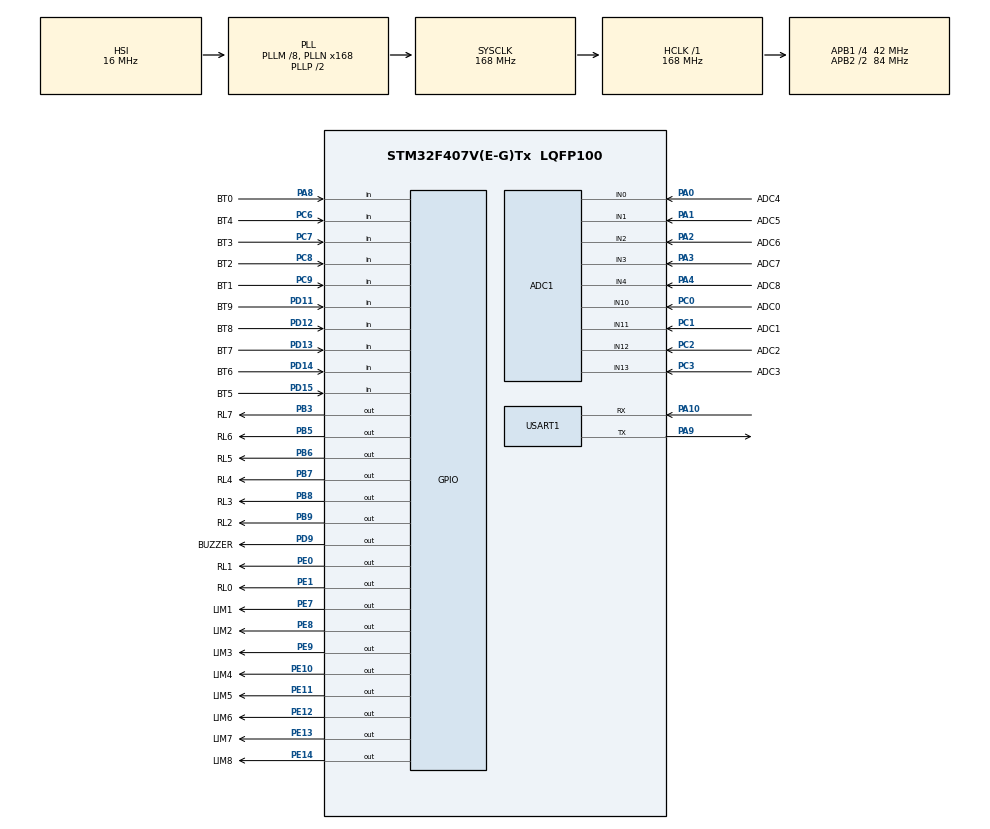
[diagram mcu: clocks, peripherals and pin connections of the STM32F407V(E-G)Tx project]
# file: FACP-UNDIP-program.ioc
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ADC1.Channel-16\#ChannelRegularConversion=ADC_CHANNEL_10
ADC1.NbrOfConversionFlag=1
ADC1.Rank-16\#ChannelRegularConversion=1
ADC1.SamplingTime-16\#ChannelRegularConversion=ADC_SAMPLETIME_3CYCLES
ADC1.master=1
Dma.Request0=USART1_RX
Dma.USART1_RX.0.Direction=DMA_PERIPH_TO_MEMORY
Dma.USART1_RX.0.FIFOMode=DMA_FIFOMODE_DISABLE
Dma.USART1_RX.0.Instance=DMA2_Stream2
Dma.USART1_RX.0.MemDataAlignment=DMA_MDATAALIGN_BYTE
Dma.USART1_RX.0.MemInc=DMA_MINC_ENABLE
Dma.USART1_RX.0.Mode=DMA_NORMAL
Dma.USART1_RX.0.PeriphDataAlignment=DMA_PDATAALIGN_BYTE
Dma.USART1_RX.0.PeriphInc=DMA_PINC_DISABLE
Dma.USART1_RX.0.Priority=DMA_PRIORITY_LOW
Mcu.Family=STM32F4
Mcu.Name=STM32F407V(E-G)Tx
Mcu.Package=LQFP100
NVIC.DMA2_Stream2_IRQn=true\:0\:0\:false\:false\:true\:false\:true\:true
NVIC.PriorityGroup=NVIC_PRIORITYGROUP_4
NVIC.USART1_IRQn=true\:0\:0\:false\:false\:true\:true\:true\:true
PA0-WKUP.GPIO_Label=ADC4
PA0-WKUP.Signal=ADCx_IN0
PA1.GPIO_Label=ADC5
PA1.Signal=ADCx_IN1
PA10.Mode=Asynchronous
PA10.Signal=USART1_RX
PA13.Mode=Serial_Wire
PA13.Signal=SYS_JTMS-SWDIO
PA14.Mode=Serial_Wire
PA14.Signal=SYS_JTCK-SWCLK
PA2.GPIO_Label=ADC6
PA2.Signal=ADCx_IN2
PA3.GPIO_Label=ADC7
PA3.Signal=ADCx_IN3
PA4.GPIO_Label=ADC8
PA4.Signal=ADCx_IN4
PA8.GPIO_Label=BT0
PA8.Signal=GPIO_Input
PA9.Mode=Asynchronous
PA9.Signal=USART1_TX
PB3.GPIO_Label=RL7
PB3.Signal=GPIO_Output
PB5.GPIO_Label=RL6
PB5.Signal=GPIO_Output
PB6.GPIO_Label=RL5
PB6.Signal=GPIO_Output
PB7.GPIO_Label=RL4
PB7.Signal=GPIO_Output
PB8.GPIO_Label=RL3
PB8.Signal=GPIO_Output
PB9.GPIO_Label=RL2
PB9.Signal=GPIO_Output
PC0.GPIO_Label=ADC0
PC0.Signal=ADCx_IN10
PC1.GPIO_Label=ADC1
PC1.Signal=ADCx_IN11
PC2.GPIO_Label=ADC2
PC2.Signal=ADCx_IN12
PC3.GPIO_Label=ADC3
PC3.Signal=ADCx_IN13
PC6.GPIO_Label=BT4
PC6.Signal=GPIO_Input
PC7.GPIO_Label=BT3
PC7.Signal=GPIO_Input
PC8.GPIO_Label=BT2
PC8.Signal=GPIO_Input
PC9.GPIO_Label=BT1
PC9.Signal=GPIO_Input
PD11.GPIO_Label=BT9
PD11.Signal=GPIO_Input
PD12.GPIO_Label=BT8
PD12.Signal=GPIO_Input
PD13.GPIO_Label=BT7
PD13.Signal=GPIO_Input
PD14.GPIO_Label=BT6
PD14.Signal=GPIO_Input
PD15.GPIO_Label=BT5
PD15.Signal=GPIO_Input
PD9.GPIO_Label=BUZZER
PD9.Signal=GPIO_Output
PE0.GPIO_Label=RL1
PE0.Signal=GPIO_Output
PE1.GPIO_Label=RL0
PE1.Signal=GPIO_Output
PE10.GPIO_Label=LIM4
PE10.Signal=GPIO_Output
PE11.GPIO_Label=LIM5
PE11.Signal=GPIO_Output
PE12.GPIO_Label=LIM6
PE12.Signal=GPIO_Output
PE13.GPIO_Label=LIM7
PE13.Signal=GPIO_Output
PE14.GPIO_Label=LIM8
PE14.Signal=GPIO_Output
PE7.GPIO_Label=LIM1
PE7.Signal=GPIO_Output
PE8.GPIO_Label=LIM2
PE8.Signal=GPIO_Output
PE9.GPIO_Label=LIM3
PE9.Signal=GPIO_Output
PH0-OSC_IN.Mode=HSE-External-Oscillator
PH0-OSC_IN.Signal=RCC_OSC_IN
PH1-OSC_OUT.Mode=HSE-External-Oscillator
PH1-OSC_OUT.Signal=RCC_OSC_OUT
ProjectManager.HeapSize=0x200
ProjectManager.StackSize=0x400
ProjectManager.TargetToolchain=MDK-ARM V5.32
RCC.48MHZClocksFreq_Value=84000000
RCC.AHBFreq_Value=168000000
RCC.APB1CLKDivider=RCC_HCLK_DIV4
RCC.APB1Freq_Value=42000000
RCC.APB1TimFreq_Value=84000000
RCC.APB2CLKDivider=RCC_HCLK_DIV2
RCC.APB2Freq_Value=84000000
RCC.APB2TimFreq_Value=168000000
RCC.CortexFreq_Value=168000000
RCC.HCLKFreq_Value=168000000
RCC.HSE_VALUE=25000000
RCC.HSI_VALUE=16000000
RCC.LSE_VALUE=32768
RCC.PLLM=8
RCC.PLLN=168
RCC.SYSCLKFreq_VALUE=168000000
RCC.SYSCLKSource=RCC_SYSCLKSOURCE_PLLCLK
RCC.VCOOutputFreq_Value=336000000
SH.ADCx_IN0.0=ADC1_IN0,IN0
SH.ADCx_IN1.0=ADC1_IN1,IN1
SH.ADCx_IN10.0=ADC1_IN10,IN10
SH.ADCx_IN11.0=ADC1_IN11,IN11
SH.ADCx_IN12.0=ADC1_IN12,IN12
SH.ADCx_IN13.0=ADC1_IN13,IN13
SH.ADCx_IN2.0=ADC1_IN2,IN2
SH.ADCx_IN3.0=ADC1_IN3,IN3
SH.ADCx_IN4.0=ADC1_IN4,IN4
USART1.VirtualMode=VM_ASYNC
board=custom

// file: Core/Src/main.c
/* USER CODE BEGIN Header */
/**
  ******************************************************************************
  * @file           : main.c
  * @brief          : Main program body
  ******************************************************************************
  * @attention
  *
  * Copyright (c) 2023 STMicroelectronics.
  * All rights reserved.
  *
  * This software is licensed under terms that can be found in the LICENSE file
  * in the root directory of this software component.
  * If no LICENSE file comes with this software, it is provided AS-IS.
  *
  ******************************************************************************
  */
/* USER CODE END Header */
#include "main.h"
#include "stdbool.h"
#include "stdio.h"
#include "Header.h"
#include "LCD_Lib.h"
#include "DWT_Delay.h"

ADC_HandleTypeDef hadc1;

UART_HandleTypeDef huart1;
DMA_HandleTypeDef hdma_usart1_rx;

/* USER CODE BEGIN PV */
char bufferr[128];
bool systemSetOK = false;
uint32_t adcBuffer[16];
/* USER CODE END PV */

void SystemClock_Config(void);
static void MX_GPIO_Init(void);
static void MX_DMA_Init(void);
static void MX_ADC1_Init(void);
static void MX_USART1_UART_Init(void);

int main(void)
{

  /* MCU Configuration--------------------------------------------------------*/

  /* Reset of all peripherals, Initializes the Flash interface and the Systick. */
  HAL_Init();

  /* Configure the system clock */
  SystemClock_Config();

  /* Initialize all configured peripherals */
  MX_GPIO_Init();
  MX_DMA_Init();
  MX_ADC1_Init();
  MX_USART1_UART_Init();
  /* USER CODE BEGIN 2 */
	HAL_ADC_Start_DMA(&hadc1, adcBuffer, 8);
	LCD_Init(40,2);
	LCD_CursorSet(0,0);
	LCD_Putsxy(0, 0,"====> MUTANT 3.0 <====");
	LCD_Putsxy(0, 1,"   ==> SV UNDIP <==");
	DWT_Delayms(1000);
	LCD_Clear();
  /* USER CODE END 2 */

  /* Infinite loop */
  while (1)
  {
		//LCD_Putsxy(0, 0,"====> MUTANT 3.0 <====");
		//LCD_Putsxy(0, 1,"==> SV UNDIP <==");
//		if(systemSetOK == false){
//			while(1){
//				if(systemSetOK == false){
//					systemSetOK =  selectMenu();
//					//limitOn(0xFF);
//					LCD_Clear();
//				}else{
//					sprintf(bufferr, "MODE %d || INT %d", selectedSensingMode, valueSetInterval);
//					LCD_Putsxy(0,0, "SYSTEM RUNNING");
//					LCD_Putsxy(0,1, bufferr);
//					//sendDateTime();
//					//if(flagRx == true){parsingDataF1();}					//Parsing DATA
//					DWT_Delayms(2000);
//					LCD_Clear();
//					break;
//				}
//			}
//		}else{
//		// JALANKAN PROGRAM RUNNING SYSTEM IN HERE
//			if(selectedSensingMode == 1){
//				LCD_Putsxy(14,0, "MUTANT 2.0");
//				//LCD_Putsxy(10, 1, dateTime);
//				//if(flagRx == true){parsingDataF1();}					//Parsing DATA
//				modeSingleWire();
//				//checkSortAndOpenCircuit();
//				//checkSupply();
//			}else if(selectedSensingMode == 2){
//				LCD_Putsxy(14,0, "MUTANT 2.0");
//				//LCD_Putsxy(10, 1, dateTime);
//				//if(flagRx == true){parsingDataF1();}					//Parsing DATA
//				modeCrossWire();
//				//checkSortAndOpenCircuit();
//				//checkSupply();
//			}
//		}
  }
}

void SystemClock_Config(void)
{
  RCC_OscInitTypeDef RCC_OscInitStruct = {0};
  RCC_ClkInitTypeDef RCC_ClkInitStruct = {0};

  /** Configure the main internal regulator output voltage
  */
  __HAL_RCC_PWR_CLK_ENABLE();
  __HAL_PWR_VOLTAGESCALING_CONFIG(PWR_REGULATOR_VOLTAGE_SCALE1);

  /** Initializes the RCC Oscillators according to the specified parameters
  * in the RCC_OscInitTypeDef structure.
  */
  RCC_OscInitStruct.OscillatorType = RCC_OSCILLATORTYPE_HSI;
  RCC_OscInitStruct.HSIState = RCC_HSI_ON;
  RCC_OscInitStruct.HSICalibrationValue = RCC_HSICALIBRATION_DEFAULT;
  RCC_OscInitStruct.PLL.PLLState = RCC_PLL_ON;
  RCC_OscInitStruct.PLL.PLLSource = RCC_PLLSOURCE_HSI;
  RCC_OscInitStruct.PLL.PLLM = 8;
  RCC_OscInitStruct.PLL.PLLN = 168;
  RCC_OscInitStruct.PLL.PLLP = RCC_PLLP_DIV2;
  RCC_OscInitStruct.PLL.PLLQ = 4;
  if (HAL_RCC_OscConfig(&RCC_OscInitStruct) != HAL_OK)
  {
    Error_Handler();
  }

  /** Initializes the CPU, AHB and APB buses clocks
  */
  RCC_ClkInitStruct.ClockType = RCC_CLOCKTYPE_HCLK|RCC_CLOCKTYPE_SYSCLK
                              |RCC_CLOCKTYPE_PCLK1|RCC_CLOCKTYPE_PCLK2;
  RCC_ClkInitStruct.SYSCLKSource = RCC_SYSCLKSOURCE_PLLCLK;
  RCC_ClkInitStruct.AHBCLKDivider = RCC_SYSCLK_DIV1;
  RCC_ClkInitStruct.APB1CLKDivider = RCC_HCLK_DIV4;
  RCC_ClkInitStruct.APB2CLKDivider = RCC_HCLK_DIV2;

  if (HAL_RCC_ClockConfig(&RCC_ClkInitStruct, FLASH_LATENCY_5) != HAL_OK)
  {
    Error_Handler();
  }
}

static void MX_ADC1_Init(void)
{

  ADC_ChannelConfTypeDef sConfig = {0};

  /** Configure the global features of the ADC (Clock, Resolution, Data Alignment and number of conversion)
  */
  hadc1.Instance = ADC1;
  hadc1.Init.ClockPrescaler = ADC_CLOCK_SYNC_PCLK_DIV4;
  hadc1.Init.Resolution = ADC_RESOLUTION_12B;
  hadc1.Init.ScanConvMode = DISABLE;
  hadc1.Init.ContinuousConvMode = DISABLE;
  hadc1.Init.DiscontinuousConvMode = DISABLE;
  hadc1.Init.ExternalTrigConvEdge = ADC_EXTERNALTRIGCONVEDGE_NONE;
  hadc1.Init.ExternalTrigConv = ADC_SOFTWARE_START;
  hadc1.Init.DataAlign = ADC_DATAALIGN_RIGHT;
  hadc1.Init.NbrOfConversion = 1;
  hadc1.Init.DMAContinuousRequests = DISABLE;
  hadc1.Init.EOCSelection = ADC_EOC_SINGLE_CONV;
  if (HAL_ADC_Init(&hadc1) != HAL_OK)
  {
    Error_Handler();
  }

  /** Configure for the selected ADC regular channel its corresponding rank in the sequencer and its sample time.
  */
  sConfig.Channel = ADC_CHANNEL_10;
  sConfig.Rank = 1;
  sConfig.SamplingTime = ADC_SAMPLETIME_3CYCLES;
  if (HAL_ADC_ConfigChannel(&hadc1, &sConfig) != HAL_OK)
  {
    Error_Handler();
  }

}

static void MX_USART1_UART_Init(void)
{

  huart1.Instance = USART1;
  huart1.Init.BaudRate = 115200;
  huart1.Init.WordLength = UART_WORDLENGTH_8B;
  huart1.Init.StopBits = UART_STOPBITS_1;
  huart1.Init.Parity = UART_PARITY_NONE;
  huart1.Init.Mode = UART_MODE_TX_RX;
  huart1.Init.HwFlowCtl = UART_HWCONTROL_NONE;
  huart1.Init.OverSampling = UART_OVERSAMPLING_16;
  if (HAL_UART_Init(&huart1) != HAL_OK)
  {
    Error_Handler();
  }

}

static void MX_DMA_Init(void)
{

  /* DMA controller clock enable */
  __HAL_RCC_DMA2_CLK_ENABLE();

  /* DMA interrupt init */
  /* DMA2_Stream2_IRQn interrupt configuration */
  HAL_NVIC_SetPriority(DMA2_Stream2_IRQn, 0, 0);
  HAL_NVIC_EnableIRQ(DMA2_Stream2_IRQn);

}

static void MX_GPIO_Init(void)
{
  GPIO_InitTypeDef GPIO_InitStruct = {0};

  /* GPIO Ports Clock Enable */
  __HAL_RCC_GPIOH_CLK_ENABLE();
  __HAL_RCC_GPIOC_CLK_ENABLE();
  __HAL_RCC_GPIOA_CLK_ENABLE();
  __HAL_RCC_GPIOE_CLK_ENABLE();
  __HAL_RCC_GPIOD_CLK_ENABLE();
  __HAL_RCC_GPIOB_CLK_ENABLE();

  /*Configure GPIO pin Output Level */
  HAL_GPIO_WritePin(GPIOE, LIM1_Pin|LIM2_Pin|LIM3_Pin|LIM4_Pin
                          |LIM5_Pin|LIM6_Pin|LIM7_Pin|LIM8_Pin
                          |RL1_Pin|RL0_Pin, GPIO_PIN_RESET);

  /*Configure GPIO pin Output Level */
  HAL_GPIO_WritePin(BUZZER_GPIO_Port, BUZZER_Pin, GPIO_PIN_RESET);

  /*Configure GPIO pin Output Level */
  HAL_GPIO_WritePin(GPIOB, RL7_Pin|RL6_Pin|RL5_Pin|RL4_Pin
                          |RL3_Pin|RL2_Pin, GPIO_PIN_RESET);

  /*Configure GPIO pins : LIM1_Pin LIM2_Pin LIM3_Pin LIM4_Pin
                           LIM5_Pin LIM6_Pin LIM7_Pin LIM8_Pin
                           RL1_Pin RL0_Pin */
  GPIO_InitStruct.Pin = LIM1_Pin|LIM2_Pin|LIM3_Pin|LIM4_Pin
                          |LIM5_Pin|LIM6_Pin|LIM7_Pin|LIM8_Pin
                          |RL1_Pin|RL0_Pin;
  GPIO_InitStruct.Mode = GPIO_MODE_OUTPUT_PP;
  GPIO_InitStruct.Pull = GPIO_NOPULL;
  GPIO_InitStruct.Speed = GPIO_SPEED_FREQ_LOW;
  HAL_GPIO_Init(GPIOE, &GPIO_InitStruct);

  /*Configure GPIO pin : BUZZER_Pin */
  GPIO_InitStruct.Pin = BUZZER_Pin;
  GPIO_InitStruct.Mode = GPIO_MODE_OUTPUT_PP;
  GPIO_InitStruct.Pull = GPIO_NOPULL;
  GPIO_InitStruct.Speed = GPIO_SPEED_FREQ_LOW;
  HAL_GPIO_Init(BUZZER_GPIO_Port, &GPIO_InitStruct);

  /*Configure GPIO pins : BT9_Pin BT8_Pin BT7_Pin BT6_Pin
                           BT5_Pin */
  GPIO_InitStruct.Pin = BT9_Pin|BT8_Pin|BT7_Pin|BT6_Pin
                          |BT5_Pin;
  GPIO_InitStruct.Mode = GPIO_MODE_INPUT;
  GPIO_InitStruct.Pull = GPIO_NOPULL;
  HAL_GPIO_Init(GPIOD, &GPIO_InitStruct);

  /*Configure GPIO pins : BT4_Pin BT3_Pin BT2_Pin BT1_Pin */
  GPIO_InitStruct.Pin = BT4_Pin|BT3_Pin|BT2_Pin|BT1_Pin;
  GPIO_InitStruct.Mode = GPIO_MODE_INPUT;
  GPIO_InitStruct.Pull = GPIO_NOPULL;
  HAL_GPIO_Init(GPIOC, &GPIO_InitStruct);

  /*Configure GPIO pin : BT0_Pin */
  GPIO_InitStruct.Pin = BT0_Pin;
  GPIO_InitStruct.Mode = GPIO_MODE_INPUT;
  GPIO_InitStruct.Pull = GPIO_NOPULL;
  HAL_GPIO_Init(BT0_GPIO_Port, &GPIO_InitStruct);

  /*Configure GPIO pins : RL7_Pin RL6_Pin RL5_Pin RL4_Pin
                           RL3_Pin RL2_Pin */
  GPIO_InitStruct.Pin = RL7_Pin|RL6_Pin|RL5_Pin|RL4_Pin
                          |RL3_Pin|RL2_Pin;
  GPIO_InitStruct.Mode = GPIO_MODE_OUTPUT_PP;
  GPIO_InitStruct.Pull = GPIO_NOPULL;
  GPIO_InitStruct.Speed = GPIO_SPEED_FREQ_LOW;
  HAL_GPIO_Init(GPIOB, &GPIO_InitStruct);

}

void Error_Handler(void)
{
  __disable_irq();
  while (1)
  {
  }
}
